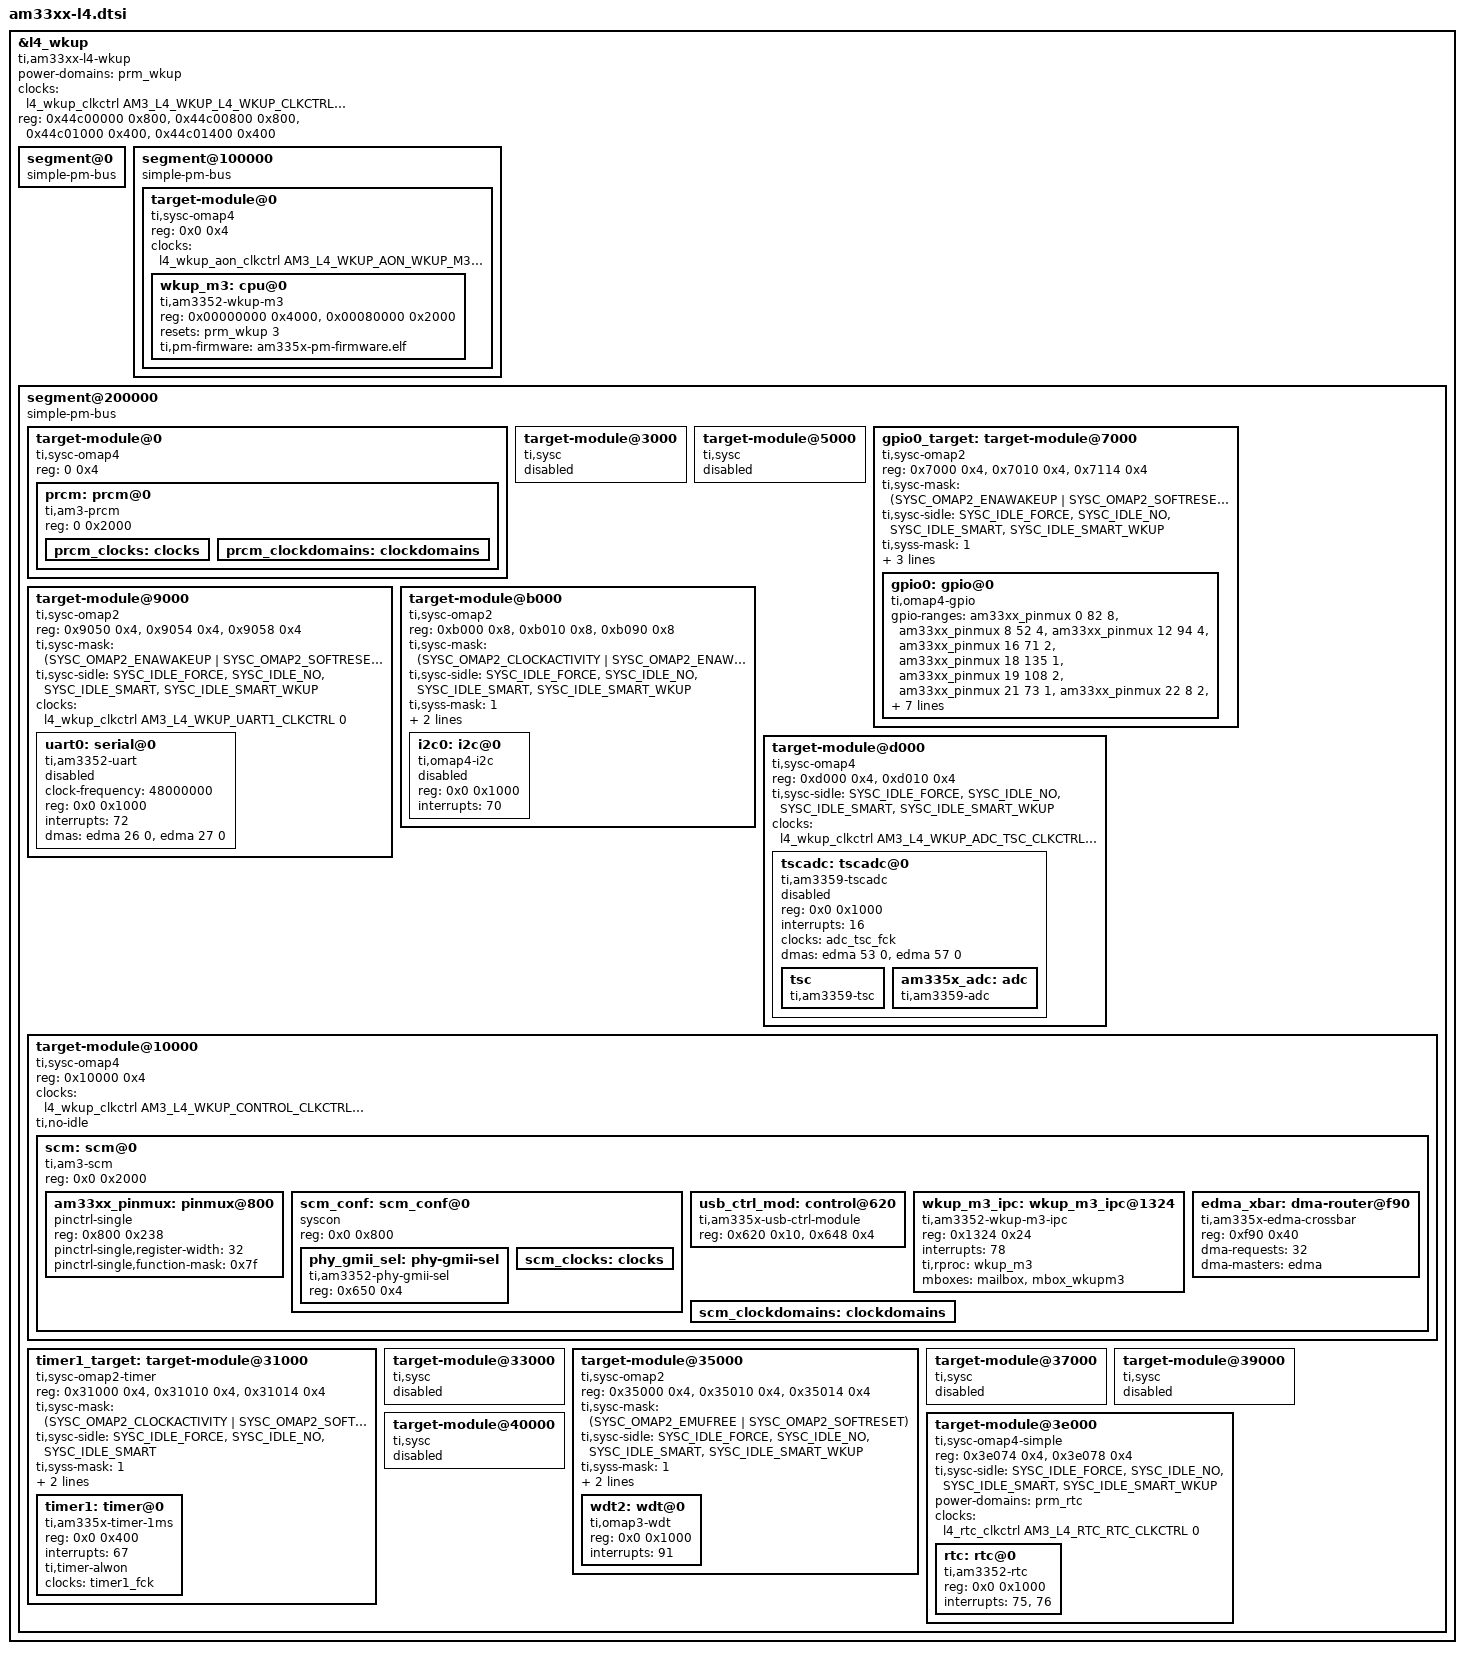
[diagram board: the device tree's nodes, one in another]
&l4_wkup {						/* 0x44c00000 */
	compatible = "ti,am33xx-l4-wkup", "simple-pm-bus";
	power-domains = <&prm_wkup>;
	clocks = <&l4_wkup_clkctrl AM3_L4_WKUP_L4_WKUP_CLKCTRL 0>;
	clock-names = "fck";
	reg = <0x44c00000 0x800>,
	      <0x44c00800 0x800>,
	      <0x44c01000 0x400>,
	      <0x44c01400 0x400>;
	reg-names = "ap", "la", "ia0", "ia1";
	#address-cells = <1>;
	#size-cells = <1>;
	ranges = <0x00000000 0x44c00000 0x100000>,	/* segment 0 */
		 <0x00100000 0x44d00000 0x100000>,	/* segment 1 */
		 <0x00200000 0x44e00000 0x100000>;	/* segment 2 */

	segment@0 {					/* 0x44c00000 */
		compatible = "simple-pm-bus";
		#address-cells = <1>;
		#size-cells = <1>;
		ranges = <0x00000000 0x00000000 0x000800>,	/* ap 0 */
			 <0x00000800 0x00000800 0x000800>,	/* ap 1 */
			 <0x00001000 0x00001000 0x000400>,	/* ap 2 */
			 <0x00001400 0x00001400 0x000400>;	/* ap 3 */
	};

	segment@100000 {					/* 0x44d00000 */
		compatible = "simple-pm-bus";
		#address-cells = <1>;
		#size-cells = <1>;
		ranges = <0x00000000 0x00100000 0x004000>,	/* ap 4 */
			 <0x00004000 0x00104000 0x001000>,	/* ap 5 */
			 <0x00080000 0x00180000 0x002000>,	/* ap 6 */
			 <0x00082000 0x00182000 0x001000>;	/* ap 7 */

		target-module@0 {			/* 0x44d00000, ap 4 28.0 */
			compatible = "ti,sysc-omap4", "ti,sysc";
			reg = <0x0 0x4>;
			reg-names = "rev";
			clocks = <&l4_wkup_aon_clkctrl AM3_L4_WKUP_AON_WKUP_M3_CLKCTRL 0>;
			clock-names = "fck";
			#address-cells = <1>;
			#size-cells = <1>;
			ranges = <0x00000000 0x00000000 0x4000>,
				 <0x00080000 0x00080000 0x2000>;

			wkup_m3: cpu@0 {
				compatible = "ti,am3352-wkup-m3";
				reg = <0x00000000 0x4000>,
				      <0x00080000 0x2000>;
				reg-names = "umem", "dmem";
				resets = <&prm_wkup 3>;
				reset-names = "rstctrl";
				ti,pm-firmware = "am335x-pm-firmware.elf";
			};
		};
	};

	segment@200000 {					/* 0x44e00000 */
		compatible = "simple-pm-bus";
		#address-cells = <1>;
		#size-cells = <1>;
		ranges = <0x00000000 0x00200000 0x002000>,	/* ap 8 */
			 <0x00002000 0x00202000 0x001000>,	/* ap 9 */
			 <0x00003000 0x00203000 0x001000>,	/* ap 10 */
			 <0x00004000 0x00204000 0x001000>,	/* ap 11 */
			 <0x00005000 0x00205000 0x001000>,	/* ap 12 */
			 <0x00006000 0x00206000 0x001000>,	/* ap 13 */
			 <0x00007000 0x00207000 0x001000>,	/* ap 14 */
			 <0x00008000 0x00208000 0x001000>,	/* ap 15 */
			 <0x00009000 0x00209000 0x001000>,	/* ap 16 */
			 <0x0000a000 0x0020a000 0x001000>,	/* ap 17 */
			 <0x0000b000 0x0020b000 0x001000>,	/* ap 18 */
			 <0x0000c000 0x0020c000 0x001000>,	/* ap 19 */
			 <0x0000d000 0x0020d000 0x001000>,	/* ap 20 */
			 <0x0000f000 0x0020f000 0x001000>,	/* ap 21 */
			 <0x00010000 0x00210000 0x010000>,	/* ap 22 */
			 <0x00020000 0x00220000 0x010000>,	/* ap 23 */
			 <0x00030000 0x00230000 0x001000>,	/* ap 24 */
			 <0x00031000 0x00231000 0x001000>,	/* ap 25 */
			 <0x00032000 0x00232000 0x001000>,	/* ap 26 */
			 <0x00033000 0x00233000 0x001000>,	/* ap 27 */
			 <0x00034000 0x00234000 0x001000>,	/* ap 28 */
			 <0x00035000 0x00235000 0x001000>,	/* ap 29 */
			 <0x00036000 0x00236000 0x001000>,	/* ap 30 */
			 <0x00037000 0x00237000 0x001000>,	/* ap 31 */
			 <0x00038000 0x00238000 0x001000>,	/* ap 32 */
			 <0x00039000 0x00239000 0x001000>,	/* ap 33 */
			 <0x0003a000 0x0023a000 0x001000>,	/* ap 34 */
			 <0x0003e000 0x0023e000 0x001000>,	/* ap 35 */
			 <0x0003f000 0x0023f000 0x001000>,	/* ap 36 */
			 <0x0000e000 0x0020e000 0x001000>,	/* ap 37 */
			 <0x00040000 0x00240000 0x040000>,	/* ap 38 */
			 <0x00080000 0x00280000 0x001000>;	/* ap 39 */

		target-module@0 {			/* 0x44e00000, ap 8 58.0 */
			compatible = "ti,sysc-omap4", "ti,sysc";
			reg = <0 0x4>;
			reg-names = "rev";
			#address-cells = <1>;
			#size-cells = <1>;
			ranges = <0x0 0x0 0x2000>;

			prcm: prcm@0 {
				compatible = "ti,am3-prcm", "simple-bus";
				reg = <0 0x2000>;
				#address-cells = <1>;
				#size-cells = <1>;
				ranges = <0 0 0x2000>;

				prcm_clocks: clocks {
					#address-cells = <1>;
					#size-cells = <0>;
				};

				prcm_clockdomains: clockdomains {
				};
			};
		};

		target-module@3000 {			/* 0x44e03000, ap 10 0a.0 */
			compatible = "ti,sysc";
			status = "disabled";
			#address-cells = <1>;
			#size-cells = <1>;
			ranges = <0x0 0x3000 0x1000>;
		};

		target-module@5000 {			/* 0x44e05000, ap 12 30.0 */
			compatible = "ti,sysc";
			status = "disabled";
			#address-cells = <1>;
			#size-cells = <1>;
			ranges = <0x0 0x5000 0x1000>;
		};

		gpio0_target: target-module@7000 {	/* 0x44e07000, ap 14 20.0 */
			compatible = "ti,sysc-omap2", "ti,sysc";
			reg = <0x7000 0x4>,
			      <0x7010 0x4>,
			      <0x7114 0x4>;
			reg-names = "rev", "sysc", "syss";
			ti,sysc-mask = <(SYSC_OMAP2_ENAWAKEUP |
					 SYSC_OMAP2_SOFTRESET |
					 SYSC_OMAP2_AUTOIDLE)>;
			ti,sysc-sidle = <SYSC_IDLE_FORCE>,
					<SYSC_IDLE_NO>,
					<SYSC_IDLE_SMART>,
					<SYSC_IDLE_SMART_WKUP>;
			ti,syss-mask = <1>;
			/* Domains (P, C): wkup_pwrdm, l4_wkup_clkdm */
			clocks = <&l4_wkup_clkctrl AM3_L4_WKUP_GPIO1_CLKCTRL 0>,
				 <&l4_wkup_clkctrl AM3_L4_WKUP_GPIO1_CLKCTRL 18>;
			clock-names = "fck", "dbclk";
			#address-cells = <1>;
			#size-cells = <1>;
			ranges = <0x0 0x7000 0x1000>;

			gpio0: gpio@0 {
				compatible = "ti,omap4-gpio";
				gpio-ranges =	<&am33xx_pinmux  0  82 8>,
						<&am33xx_pinmux  8  52 4>,
						<&am33xx_pinmux 12  94 4>,
						<&am33xx_pinmux 16  71 2>,
						<&am33xx_pinmux 18 135 1>,
						<&am33xx_pinmux 19 108 2>,
						<&am33xx_pinmux 21  73 1>,
						<&am33xx_pinmux 22   8 2>,
						<&am33xx_pinmux 26  10 2>,
						<&am33xx_pinmux 28  74 1>,
						<&am33xx_pinmux 29  81 1>,
						<&am33xx_pinmux 30  28 2>;
				gpio-controller;
				#gpio-cells = <2>;
				interrupt-controller;
				#interrupt-cells = <2>;
				reg = <0x0 0x1000>;
				interrupts = <96>;
			};
		};

		target-module@9000 {			/* 0x44e09000, ap 16 04.0 */
			compatible = "ti,sysc-omap2", "ti,sysc";
			reg = <0x9050 0x4>,
			      <0x9054 0x4>,
			      <0x9058 0x4>;
			reg-names = "rev", "sysc", "syss";
			ti,sysc-mask = <(SYSC_OMAP2_ENAWAKEUP |
					 SYSC_OMAP2_SOFTRESET |
					 SYSC_OMAP2_AUTOIDLE)>;
			ti,sysc-sidle = <SYSC_IDLE_FORCE>,
					<SYSC_IDLE_NO>,
					<SYSC_IDLE_SMART>,
					<SYSC_IDLE_SMART_WKUP>;
			/* Domains (P, C): wkup_pwrdm, l4_wkup_clkdm */
			clocks = <&l4_wkup_clkctrl AM3_L4_WKUP_UART1_CLKCTRL 0>;
			clock-names = "fck";
			#address-cells = <1>;
			#size-cells = <1>;
			ranges = <0x0 0x9000 0x1000>;

			uart0: serial@0 {
				compatible = "ti,am3352-uart";
				clock-frequency = <48000000>;
				reg = <0x0 0x1000>;
				interrupts = <72>;
				status = "disabled";
				dmas = <&edma 26 0>, <&edma 27 0>;
				dma-names = "tx", "rx";
			};
		};

		target-module@b000 {			/* 0x44e0b000, ap 18 48.0 */
			compatible = "ti,sysc-omap2", "ti,sysc";
			reg = <0xb000 0x8>,
			      <0xb010 0x8>,
			      <0xb090 0x8>;
			reg-names = "rev", "sysc", "syss";
			ti,sysc-mask = <(SYSC_OMAP2_CLOCKACTIVITY |
					 SYSC_OMAP2_ENAWAKEUP |
					 SYSC_OMAP2_SOFTRESET |
					 SYSC_OMAP2_AUTOIDLE)>;
			ti,sysc-sidle = <SYSC_IDLE_FORCE>,
					<SYSC_IDLE_NO>,
					<SYSC_IDLE_SMART>,
					<SYSC_IDLE_SMART_WKUP>;
			ti,syss-mask = <1>;
			/* Domains (P, C): wkup_pwrdm, l4_wkup_clkdm */
			clocks = <&l4_wkup_clkctrl AM3_L4_WKUP_I2C1_CLKCTRL 0>;
			clock-names = "fck";
			#address-cells = <1>;
			#size-cells = <1>;
			ranges = <0x0 0xb000 0x1000>;

			i2c0: i2c@0 {
				compatible = "ti,omap4-i2c";
				#address-cells = <1>;
				#size-cells = <0>;
				reg = <0x0 0x1000>;
				interrupts = <70>;
				status = "disabled";
			};
		};

		target-module@d000 {			/* 0x44e0d000, ap 20 38.0 */
			compatible = "ti,sysc-omap4", "ti,sysc";
			reg = <0xd000 0x4>,
			      <0xd010 0x4>;
			reg-names = "rev", "sysc";
			ti,sysc-sidle = <SYSC_IDLE_FORCE>,
					<SYSC_IDLE_NO>,
					<SYSC_IDLE_SMART>,
					<SYSC_IDLE_SMART_WKUP>;
			/* Domains (P, C): wkup_pwrdm, l4_wkup_clkdm */
			clocks = <&l4_wkup_clkctrl AM3_L4_WKUP_ADC_TSC_CLKCTRL 0>;
			clock-names = "fck";
			#address-cells = <1>;
			#size-cells = <1>;
			ranges = <0x00000000 0x0000d000 0x00001000>,
				 <0x00001000 0x0000e000 0x00001000>;

			tscadc: tscadc@0 {
				compatible = "ti,am3359-tscadc";
				reg = <0x0 0x1000>;
				interrupts = <16>;
				clocks = <&adc_tsc_fck>;
				clock-names = "fck";
				status = "disabled";
				dmas = <&edma 53 0>, <&edma 57 0>;
				dma-names = "fifo0", "fifo1";

				tsc {
					compatible = "ti,am3359-tsc";
				};
				am335x_adc: adc {
					#io-channel-cells = <1>;
					compatible = "ti,am3359-adc";
				};
			};
		};

		target-module@10000 {			/* 0x44e10000, ap 22 0c.0 */
			compatible = "ti,sysc-omap4", "ti,sysc";
			reg = <0x10000 0x4>;
			reg-names = "rev";
			clocks = <&l4_wkup_clkctrl AM3_L4_WKUP_CONTROL_CLKCTRL 0>;
			clock-names = "fck";
			ti,no-idle;
			#address-cells = <1>;
			#size-cells = <1>;
			ranges = <0x00000000 0x00010000 0x00010000>,
				 <0x00010000 0x00020000 0x00010000>;

			scm: scm@0 {
				compatible = "ti,am3-scm", "simple-bus";
				reg = <0x0 0x2000>;
				#address-cells = <1>;
				#size-cells = <1>;
				#pinctrl-cells = <1>;
				ranges = <0 0 0x2000>;

				am33xx_pinmux: pinmux@800 {
					compatible = "pinctrl-single";
					reg = <0x800 0x238>;
					#pinctrl-cells = <2>;
					pinctrl-single,register-width = <32>;
					pinctrl-single,function-mask = <0x7f>;
				};

				scm_conf: scm_conf@0 {
					compatible = "syscon", "simple-bus";
					reg = <0x0 0x800>;
					#address-cells = <1>;
					#size-cells = <1>;
					ranges = <0 0 0x800>;

					phy_gmii_sel: phy-gmii-sel {
						compatible = "ti,am3352-phy-gmii-sel";
						reg = <0x650 0x4>;
						#phy-cells = <2>;
					};

					scm_clocks: clocks {
						#address-cells = <1>;
						#size-cells = <0>;
					};
				};

				usb_ctrl_mod: control@620 {
					compatible = "ti,am335x-usb-ctrl-module";
					reg = <0x620 0x10>,
					      <0x648 0x4>;
					reg-names = "phy_ctrl", "wakeup";
				};

				wkup_m3_ipc: wkup_m3_ipc@1324 {
					compatible = "ti,am3352-wkup-m3-ipc";
					reg = <0x1324 0x24>;
					interrupts = <78>;
					ti,rproc = <&wkup_m3>;
					mboxes = <&mailbox &mbox_wkupm3>;
				};

				edma_xbar: dma-router@f90 {
					compatible = "ti,am335x-edma-crossbar";
					reg = <0xf90 0x40>;
					#dma-cells = <3>;
					dma-requests = <32>;
					dma-masters = <&edma>;
				};

				scm_clockdomains: clockdomains {
				};
			};
		};

		timer1_target: target-module@31000 {	/* 0x44e31000, ap 25 40.0 */
			compatible = "ti,sysc-omap2-timer", "ti,sysc";
			reg = <0x31000 0x4>,
			      <0x31010 0x4>,
			      <0x31014 0x4>;
			reg-names = "rev", "sysc", "syss";
			ti,sysc-mask = <(SYSC_OMAP2_CLOCKACTIVITY |
					 SYSC_OMAP2_SOFTRESET |
					 SYSC_OMAP2_AUTOIDLE)>;
			ti,sysc-sidle = <SYSC_IDLE_FORCE>,
					<SYSC_IDLE_NO>,
					<SYSC_IDLE_SMART>;
			ti,syss-mask = <1>;
			/* Domains (P, C): wkup_pwrdm, l4_wkup_clkdm */
			clocks = <&l4_wkup_clkctrl AM3_L4_WKUP_TIMER1_CLKCTRL 0>;
			clock-names = "fck";
			#address-cells = <1>;
			#size-cells = <1>;
			ranges = <0x0 0x31000 0x1000>;
			status = "okay";

			timer1: timer@0 {
				compatible = "ti,am335x-timer-1ms";
				reg = <0x0 0x400>;
				interrupts = <67>;
				ti,timer-alwon;
				clocks = <&timer1_fck>;
				clock-names = "fck";
			};
		};

		target-module@33000 {			/* 0x44e33000, ap 27 18.0 */
			compatible = "ti,sysc";
			status = "disabled";
			#address-cells = <1>;
			#size-cells = <1>;
			ranges = <0x0 0x33000 0x1000>;
		};

		target-module@35000 {			/* 0x44e35000, ap 29 50.0 */
			compatible = "ti,sysc-omap2", "ti,sysc";
			reg = <0x35000 0x4>,
			      <0x35010 0x4>,
			      <0x35014 0x4>;
			reg-names = "rev", "sysc", "syss";
			ti,sysc-mask = <(SYSC_OMAP2_EMUFREE |
					 SYSC_OMAP2_SOFTRESET)>;
			ti,sysc-sidle = <SYSC_IDLE_FORCE>,
					<SYSC_IDLE_NO>,
					<SYSC_IDLE_SMART>,
					<SYSC_IDLE_SMART_WKUP>;
			ti,syss-mask = <1>;
			/* Domains (P, C): wkup_pwrdm, l4_wkup_clkdm */
			clocks = <&l4_wkup_clkctrl AM3_L4_WKUP_WD_TIMER2_CLKCTRL 0>;
			clock-names = "fck";
			#address-cells = <1>;
			#size-cells = <1>;
			ranges = <0x0 0x35000 0x1000>;

			wdt2: wdt@0 {
				compatible = "ti,omap3-wdt";
				reg = <0x0 0x1000>;
				interrupts = <91>;
			};
		};

		target-module@37000 {			/* 0x44e37000, ap 31 08.0 */
			compatible = "ti,sysc";
			status = "disabled";
			#address-cells = <1>;
			#size-cells = <1>;
			ranges = <0x0 0x37000 0x1000>;
		};

		target-module@39000 {			/* 0x44e39000, ap 33 02.0 */
			compatible = "ti,sysc";
			status = "disabled";
			#address-cells = <1>;
			#size-cells = <1>;
			ranges = <0x0 0x39000 0x1000>;
		};

		target-module@3e000 {			/* 0x44e3e000, ap 35 60.0 */
			compatible = "ti,sysc-omap4-simple", "ti,sysc";
			reg = <0x3e074 0x4>,
			      <0x3e078 0x4>;
			reg-names = "rev", "sysc";
			ti,sysc-sidle = <SYSC_IDLE_FORCE>,
					<SYSC_IDLE_NO>,
					<SYSC_IDLE_SMART>,
					<SYSC_IDLE_SMART_WKUP>;
			/* Domains (P, C): rtc_pwrdm, l4_rtc_clkdm */
			power-domains = <&prm_rtc>;
			clocks = <&l4_rtc_clkctrl AM3_L4_RTC_RTC_CLKCTRL 0>;
			clock-names = "fck";
			#address-cells = <1>;
			#size-cells = <1>;
			ranges = <0x0 0x3e000 0x1000>;

			rtc: rtc@0 {
				compatible = "ti,am3352-rtc", "ti,da830-rtc";
				reg = <0x0 0x1000>;
				interrupts = <75>,
					     <76>;
			};
		};

		target-module@40000 {			/* 0x44e40000, ap 38 68.0 */
			compatible = "ti,sysc";
			status = "disabled";
			#address-cells = <1>;
			#size-cells = <1>;
			ranges = <0x0 0x40000 0x40000>;
		};
	};
};
